# CY8C5868AXI_LP035 register map
File version: 0.1
Registers are 32-bit, read-write, no defined reset value unless marked. A register's access mark holds for its fields unless they carry their own. Offsets are from the block's base; [hi:lo] are bit positions; {n}, {i} and the like mark numbered series; 'fields as' and 'values as' point back to an identical list.

## c1_critical_timer
Base 0x00000000
0x40006406 c1_critical_timer_COUNTER 16-bit — UDB.A0 - Current Down Counter Value
0x40006426 c1_critical_timer_PERIOD 16-bit — UDB.D0 - Assigned Period
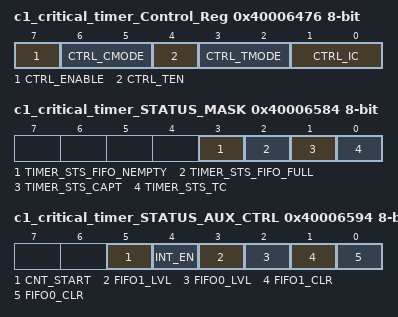
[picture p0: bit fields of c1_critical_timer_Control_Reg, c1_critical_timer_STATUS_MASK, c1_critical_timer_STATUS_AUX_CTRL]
0x40006476 c1_critical_timer_Control_Reg 8-bit — UDB Control Register - Assigned Control Register Value
  [7] CTRL_ENABLE — Enable the Timer
  [6:5] CTRL_CMODE — Capture Mode
  [4] CTRL_TEN — Trigger Enable Bit
  [3:2] CTRL_TMODE — Trigger Mode
  [1:0] CTRL_IC — Interrupt Count
0x40006584 c1_critical_timer_STATUS_MASK 8-bit — UDB Status bits Interrupt Mask Enable Register
  [3] TIMER_STS_FIFO_NEMPTY ro — FIFO Empty status
  [2] TIMER_STS_FIFO_FULL ro — FIFO Full Status
  [1] TIMER_STS_CAPT ro — Enables the Interrupt on Capture
  [0] TIMER_STS_TC ro — Enables the Interrupt on TC
0x40006594 c1_critical_timer_STATUS_AUX_CTRL 8-bit — UDB Auxilliary Control Register
  [5] CNT_START — FIFO0 clear
    0=E_CNT_START0 (Disable counter); 1=E_CNT_START1 (Enable counter)
  [4] INT_EN
    0=E_INT_EN0 (Interrupt disabled); 1=E_INT_EN1 (Interrupt enabled)
  [3] FIFO1_LVL — FIFO level
    0=E_FIFO_LVL_0 (FIFO LVL: input mode: FIFO not full; output mode: FIFO not empty); 1=E_FIFO_LVL_1 (FIFO LVL: input mode: FIFO at least 1/2 empty; output mode: FIFO at least 1/2 full)
  [2] FIFO0_LVL — FIFO level
    values as FIFO1_LVL
  [1] FIFO1_CLR — FIFO1 clear
    0=E_FIFO_CLR_0 (Normal FIFO operation); 1=E_FIFO_CLR_1 (Clear FIFO state)
  [0] FIFO0_CLR — FIFO0 clear
    values as FIFO1_CLR

## b3_critical_timer
Base 0x00000000
0x4000640A b3_critical_timer_COUNTER 16-bit — UDB.A0 - Current Down Counter Value
0x4000642A b3_critical_timer_PERIOD 16-bit — UDB.D0 - Assigned Period
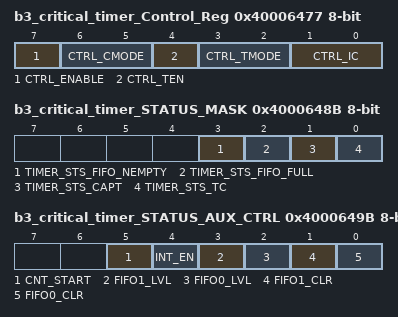
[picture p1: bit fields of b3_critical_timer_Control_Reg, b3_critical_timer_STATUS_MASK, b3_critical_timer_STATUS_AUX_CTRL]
0x40006477 b3_critical_timer_Control_Reg 8-bit — UDB Control Register - Assigned Control Register Value
  [7] CTRL_ENABLE — Enable the Timer
  [6:5] CTRL_CMODE — Capture Mode
  [4] CTRL_TEN — Trigger Enable Bit
  [3:2] CTRL_TMODE — Trigger Mode
  [1:0] CTRL_IC — Interrupt Count
0x4000648B b3_critical_timer_STATUS_MASK 8-bit — UDB Status bits Interrupt Mask Enable Register
  [3] TIMER_STS_FIFO_NEMPTY ro — FIFO Empty status
  [2] TIMER_STS_FIFO_FULL ro — FIFO Full Status
  [1] TIMER_STS_CAPT ro — Enables the Interrupt on Capture
  [0] TIMER_STS_TC ro — Enables the Interrupt on TC
0x4000649B b3_critical_timer_STATUS_AUX_CTRL 8-bit — UDB Auxilliary Control Register
  [5] CNT_START — FIFO0 clear
    0=E_CNT_START0 (Disable counter); 1=E_CNT_START1 (Enable counter)
  [4] INT_EN
    0=E_INT_EN0 (Interrupt disabled); 1=E_INT_EN1 (Interrupt enabled)
  [3] FIFO1_LVL — FIFO level
    0=E_FIFO_LVL_0 (FIFO LVL: input mode: FIFO not full; output mode: FIFO not empty); 1=E_FIFO_LVL_1 (FIFO LVL: input mode: FIFO at least 1/2 empty; output mode: FIFO at least 1/2 full)
  [2] FIFO0_LVL — FIFO level
    values as FIFO1_LVL
  [1] FIFO1_CLR — FIFO1 clear
    0=E_FIFO_CLR_0 (Normal FIFO operation); 1=E_FIFO_CLR_1 (Clear FIFO state)
  [0] FIFO0_CLR — FIFO0 clear
    values as FIFO1_CLR

## CAN
Base 0x00000000
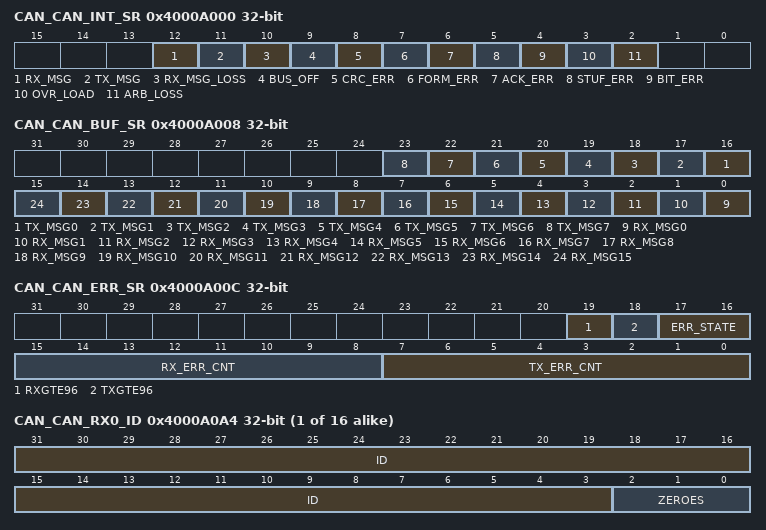
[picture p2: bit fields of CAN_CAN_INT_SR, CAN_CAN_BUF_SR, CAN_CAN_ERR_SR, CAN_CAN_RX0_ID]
0x4000A000 CAN_CAN_INT_SR — The interrupt status register stores internal interrupt events. ? Once a bit is set it remains set until it is cleared by writing a '1' to it. ? The interrupt enable register has no effect on the interrupt status register. ? A pending interrupt occurs when the flag is set to '1'. To acknowledge an interrupt, set the flag to '1'
  [12] RX_MSG — Msg Recieved
  [11] TX_MSG — Tx msg Sent
  [10] RX_MSG_LOSS — Rx msg loss Interrupt
  [9] BUS_OFF — Bus Off State
  [8] CRC_ERR — CRC Error Interrupt
  [7] FORM_ERR — Form Error Interrupt
  [6] ACK_ERR — Ack Error Interrupt
  [5] STUF_ERR — Stuff Error Interrupt
  [4] BIT_ERR — Bit Error Interrupt
  [3] OVR_LOAD — Overload Interrupt
  [2] ARB_LOSS — Arbitration Loss
0x4000A008 CAN_CAN_BUF_SR — These status indicators bundle the respective flags from all RxMessage and TxMessage buffers. ? Note All flags are read only. To acknowledge a MsgAv flag, the CPU must write to the respective RxMessage buffer
  [n+16] TX_MSG{n} (n=0..7) — Tx req Pending for Tx Msg{n}
  [n] RX_MSG{n} (n=0..15) — Rx Msg{n} Available
0x4000A00C CAN_CAN_ERR_SR — Status indicators are provided to report the CAN controller error state, receive error count, and transmit error count. ? Special flags report error counter values equal to or in excess of 96 errors are available to indicate heavily disturbed bus situations. ? The transmitter error counter according to the CAN standard. When it is greater than 255 Decimal, it is fixed at 255 Decimal.
  [19] RXGTE96 — Rx Error Count is greater or equal to 96 Decimal
  [18] TXGTE96 — Tx Error Count is greater or equal to 96 Decimal
  [17:16] ERR_STATE — Error State of CAN node, 00 error active, 01 error passive, 1x bus off
  [15:8] RX_ERR_CNT — Rx error Count. When in bus-off state,this counter is used to count 128 groups of 11 recessive bits
  [7:0] TX_ERR_CNT — Tx error Count
{0x4000A024+0x10*i} CAN_CAN_TX{i}_ID (i=0..7) — CAN Tx Msg Identifier
  [31:3] ID — Tx Msg Indentifier
{0x4000A028+0x10*i} CAN_CAN_TX{i}_DH (i=0..7) — CAN Tx Msg Upper Data Bytes
  [31:0] DATA_HIGH — Upper Data Bytes
{0x4000A02C+0x10*i} CAN_CAN_TX{i}_DL (i=0..7) — CAN Tx Msg Lower Data Bytes
  [31:0] DATA_LOW — Lower Data Bytes
{0x4000A0A4+0x20*i} CAN_CAN_RX{i}_ID (i=0..15) — The register contains Rx Msg Identifier
  [31:3] ID — Rx Msg Indentifier
  [2:0] ZEROES — zeros
{0x4000A0A8+0x20*i} CAN_CAN_RX{i}_DH (i=0..15) — The register contains the Rx Msg Upper Data Bytes
  [31:0] DATA_HIGH — Upper Data Bytes
{0x4000A0AC+0x20*i} CAN_CAN_RX{i}_DL (i=0..15) — The register contains the Rx Msg Lover Data Bytes
  [31:0] DATA_LOW — Lower Data Bytes

## CAN_Timer
Base 0x00000000
0x400043A3 CAN_Timer_GLOBAL_ENABLE 8-bit — PM.ACT.CFG
  [3:0] en_timer — Enable timer/counters.
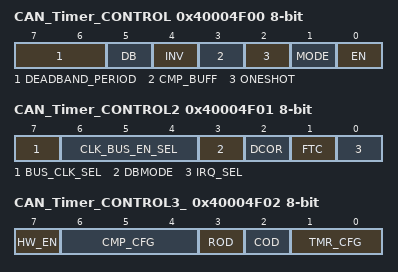
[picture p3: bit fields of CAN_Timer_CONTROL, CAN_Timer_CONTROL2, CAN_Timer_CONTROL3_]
0x40004F00 CAN_Timer_CONTROL 8-bit — TMRx.CFG0
  [7:6] DEADBAND_PERIOD
  [5] DB — Deadband mode--Deadband phases phi1 and phi2 are outputted on CMP and TC output pins respectively.
    0=Timer (CMP and TC are output.); 1=Deadband (PHI1 (instead of CMP) and PHI2 (instead of TC) are output.)
  [4] INV — Invert sense of TIMEREN signal
  [3] CMP_BUFF — Buffer compare register. Compare register updates only on timer terminal count.
  [2] ONESHOT — Timer stops upon reaching stop condition defined by TMR_CFG bits. Can be restarted by asserting TIMER RESET or disabling and re-enabling block.
  [1] MODE — Mode. (0 = Timer; 1 = Comparator)
    0=Timer mode. CNT/CMP register holds timer count value.; 1=Comparator mode. CNT/CMP register holds comparator threshold value.
  [0] EN — Enables timer/comparator.
0x40004F01 CAN_Timer_CONTROL2 8-bit — TMRx.CFG1
  [7] BUS_CLK_SEL — Bus Clock selection.
  [6:4] CLK_BUS_EN_SEL — Digital Global Clock selection.
  [3] DBMODE — Deadband mode (asynchronous/synchronous). CMP output pin is also affected when not in deadband mode (CFG0.DEADBAND).
  [2] DCOR — Disable Clear on Read (DCOR) of Status Register SR0.
  [1] FTC — First Terminal Count (FTC). Setting this bit forces a single pulse on the TC pin when first enabled.
    0=Disable_FTC (Disable the single cycle pulse, which signifies the timer is starting.); 1=Enable_FTC (Enable the single cycle pulse, which signifies the timer is starting.)
  [0] IRQ_SEL — Irq selection. (0 = raw interrupts; 1 = status register interrupts)
0x40004F02 CAN_Timer_CONTROL3_ 8-bit — TMRx.CFG2
  [7] HW_EN — When set Timer Enable controls counting.
  [6:4] CMP_CFG — Comparator configurations
    0=Equal (Compare Equal); 1=Less_than (Compare Less Than); 2=Less_than_or_equal (Compare Less Than or Equal .); 3=Greater (Compare Greater Than .); 4=Greater_than_or_equal (Compare Greater Than or Equal)
  [3] ROD — Reset On Disable (ROD). Resets internal state of output logic
  [2] COD — Clear On Disable (COD). Clears or gates outputs to zero.
  [1:0] TMR_CFG — Timer configuration (MODE = 0): 000 = Continuous; 001 = Pulsewidth; 010 = Period; 011 = Stop on IRQ
    0=Continuous (Timer runs while EN bit of CFG0 register is set to '1'.); 1=Pulsewidth (Timer runs from positive to negative edge of TIMEREN.); 2=Period (Timer runs from positive to positive edge of TIMEREN.); 3=Irq (Timer runs until IRQ.)
0x40004F04 CAN_Timer_PERIOD 8-bit — TMRx.PER0 - Assigned Period
0x40004F06 CAN_Timer_COUNTER 8-bit — TMRx.CNT_CMP0 - Current Down Counter Value
